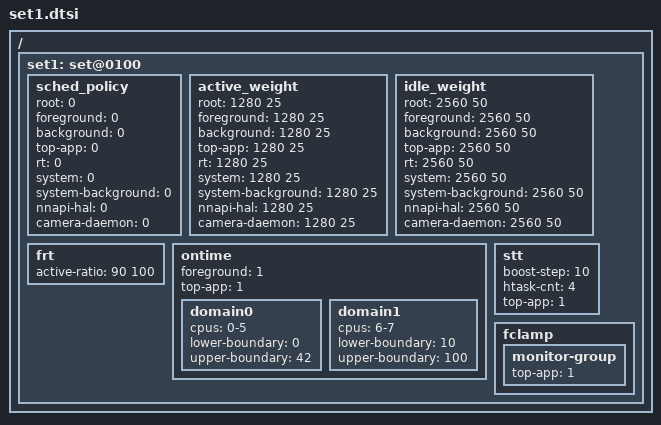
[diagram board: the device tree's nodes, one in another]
/ {
	/* power-scenario mode - default */
	set1: set@0100 {
		sched_policy {
			root = <0>;
			foreground = <0>;
			background = <0>;
			top-app = <0>;
			rt = <0>;
			system = <0>;
			system-background = <0>;
			nnapi-hal = <0>;
			camera-daemon = <0>;
		};

		active_weight {
			root = <1280 25>;
			foreground = <1280 25>;
			background = <1280 25>;
			top-app = <1280 25>;
			rt = <1280 25>;
			system = <1280 25>;
			system-background = <1280 25>;
			nnapi-hal = <1280 25>;
			camera-daemon = <1280 25>;
		};

		idle_weight {
			root = <2560 50>;
			foreground = <2560 50>;
			background = <2560 50>;
			top-app = <2560 50>;
			rt = <2560 50>;
			system = <2560 50>;
			system-background = <2560 50>;
			nnapi-hal = <2560 50>;
			camera-daemon = <2560 50>;
		};

		frt {				/* LIT BIG */
			active-ratio		= < 90 100>;
		};

		/* Ontime Migration */
		ontime {
			foreground 	= <1>;
			top-app		= <1>;

			domain0 {
				cpus = "0-5";
				lower-boundary = <0>;
				upper-boundary = <42>;
			};
			domain1 {
				cpus = "6-7";
				lower-boundary = <10>;
				upper-boundary = <100>;
			};
		};

		stt {
			boost-step = <10>;
			htask-cnt = <4>;
			top-app = <1>;
		};

		fclamp {
			monitor-group {
				top-app         = <1>;
			};
		};
	};
};
